# PIC32CM6408PL10032 register map
Vendor: Microchip Technology; Series: PIC32CMPL10; File version: 0
CPU: CM0+ r0p0, little endian, no MPU, no FPU, VTOR, 2 interrupt priority bits, 15 interrupts
Registers are 32-bit, read-write, reset 0x0 unless marked. A register's access mark holds for its fields unless they carry their own. Offsets are from the block's base; [hi:lo] are bit positions; {n}, {i} and the like mark numbered series; 'fields as' and 'values as' point back to an identical list.

## TCC0 — Timer/Counter for Control Applications
Base 0x42001800; register names take the prefix TCC_
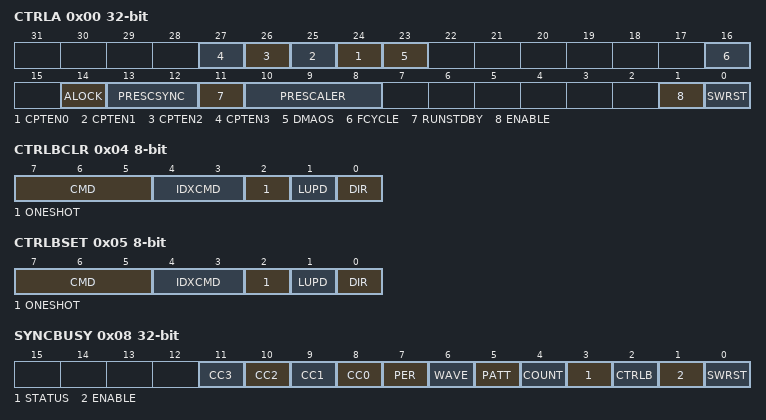
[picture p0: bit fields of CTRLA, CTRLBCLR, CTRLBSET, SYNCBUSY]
0x00 CTRLA — Control A
  [n+24] CPTEN{n} (n=0..3) — Capture Channel {n} Enable
  [23] DMAOS — DMA One-Shot Trigger Mode
  [16] FCYCLE — Full Cycle Enable
  [14] ALOCK — Auto Lock
  [13:12] PRESCSYNC — Prescaler and Counter Synchronization
    0=GCLK (Reload or reset Counter on the next GCLK); 1=PRESC (Reload or reset Counter on the next prescaler clock); 2=RESYNC (Reload or reset Counter on the next GCLK and reset prescaler counter)
  [11] RUNSTDBY — Run in Standby
  [10:8] PRESCALER
    0=DIV1 (Prescaler: GCLK_TCC); 1=DIV2 (Prescaler: GCLK_TCC/2); 2=DIV4 (Prescaler: GCLK_TCC/4); 3=DIV8 (Prescaler: GCLK_TCC/8); 4=DIV16 (Prescaler: GCLK_TCC/16); 5=DIV64 (Prescaler: GCLK_TCC/64); 6=DIV256 (Prescaler: GCLK_TCC/256); 7=DIV1024 (Prescaler: GCLK_TCC/1024)
  [1] ENABLE
  [0] SWRST — Software Reset
0x04 CTRLBCLR 8-bit write-1-clears — Control B Clear
  [7:5] CMD — TCC Command
  [4:3] IDXCMD — Ramp Index Command
  [2] ONESHOT
  [1] LUPD — Lock Update
  [0] DIR — Counter Direction
0x05 CTRLBSET 8-bit write-1-sets — Control B Set
  [7:5] CMD — TCC Command
    0=NONE (No action); 1=RETRIGGER (Force start, restart or retrigger); 2=STOP (Force stop); 3=UPDATE (Force update of double buffered registers); 4=READSYNC (Force a read synchronization of COUNT); 5=DMAOS (One-shot DMA trigger)
  [4:3] IDXCMD — Ramp Index Command
    0=DISABLE (Command disabled: IDX toggles between cycles A and B); 1=SET (Set IDX: Cycle B will be forced in the next cycle); 2=CLEAR (Clear IDX: Cycle A will be forced in next cycle); 3=HOLD (Hold IDX: The next cycle will be the same as the current cycle)
  [2] ONESHOT
  [1] LUPD — Lock Update
  [0] DIR — Counter Direction
0x08 SYNCBUSY ro — Synchronization Busy
  [n+8] CC{n} (n=0..3) — Compare/Capture Channel {n} Synchronization Busy
  [7] PER — PER Synchronization Busy
  [6] WAVE — WAVE Synchronization Busy
  [5] PATT — PATT Synchronization Busy
  [4] COUNT — COUNT Synchronization Busy
  [3] STATUS — STATUS Synchronization Busy
  [2] CTRLB — CTRLB Synchronization Busy
  [1] ENABLE — ENABLE Synchronization Busy
  [0] SWRST — SWRST Synchronization Busy
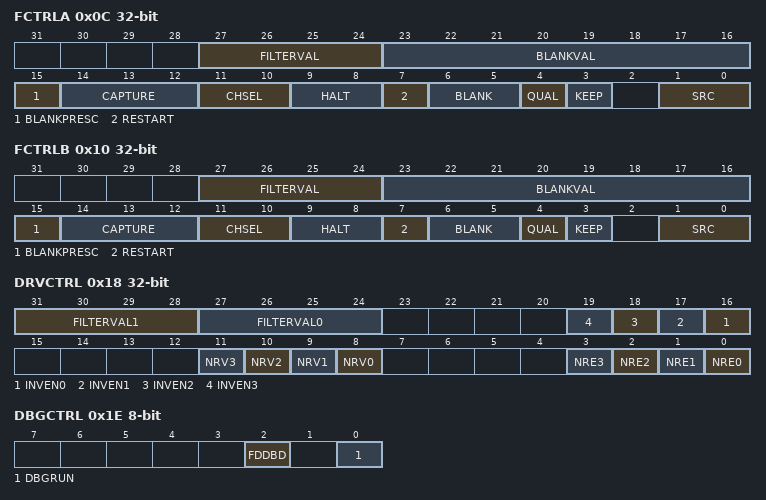
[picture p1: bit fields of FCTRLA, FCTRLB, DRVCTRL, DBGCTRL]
0x0C FCTRLA — Recoverable Fault Control #
  [27:24] FILTERVAL — Recoverable Fault Filter Value
  [23:16] BLANKVAL — Recoverable Fault Blanking Value
  [15] BLANKPRESC — Recoverable Fault Blanking Value Prescaler
  [14:12] CAPTURE — Recoverable Fault Capture Action
    0=DISABLE (Capture on valid recoverable Fault is disabled); 1=CAPT (On the rising edge of a valid recoverable fault, the counter value is captured on the channel selected by CHSEL[1:0]The INTFLAG.FAULTn flag is set on each new captured value.); 2=CAPTMIN (On the rising edge of a valid recoverable fault, the counter value is captured on the channel selected by CHSEL[1:0] if the COUNT value is lower than the last stored capture value (CC).The INTFLAG.FAULTn flag is set on each local minimum detection.); 3=CAPTMAX (On the rising edge of a valid recoverable fault, the counter value is captured on the channel selected by CHSEL[1:0] if the COUNT value is higher than the last stored capture value (CC).The INTFLAG.FAULTn flag is set on each local maximun detection.); 4=LOCMIN (On the rising edge of a valid recoverable fault, the counter value is captured on the channel selected by CHSEL[1:0].The INTFLAG.FAULTn flag is set on each local minimum value detection.); 5=LOCMAX (On the rising edge of a valid recoverable fault, the counter value is captured on the channel selected by CHSEL[1:0].The INTFLAG.FAULTn flag is set on each local maximun detection.); 6=DERIV0 (On the rising edge of a valid recoverable fault, the counter value is captured on the channel selected by CHSEL[1:0].The INTFLAG.FAULTn flag is set on each local maximun or minimum detection.); 7=CAPTMARK (Capture with the ramp index as the MSB value)
  [11:10] CHSEL — Recoverable Fault Capture Channel
    {v}=CC{v} (The captured value stored in CC{v}) (v=0..3)
  [9:8] HALT — Recoverable Fault Halt Operation
    0=DISABLE (Halt action disabled); 1=HW (Hardware halt action); 2=SW (Software halt action); 3=NR (Non-recoverable fault)
  [7] RESTART — Recoverable Fault Restart
  [6:5] BLANK — Recoverable Fault Blanking Operation
    0=START (Blanking is applied from the start of the ramp period); 1=RISE (Blanking is applied from the rising edge of the waveform output); 2=FALL (Blanking is applied from the falling edge of the waveform output); 3=BOTH (Blanking is applied from each toggle of the waveform output)
  [4] QUAL — Recoverable Fault Qualification
  [3] KEEP — Recoverable Fault Keep
  [1:0] SRC — Recoverable Fault Source
    0=DISABLE (Fault input disabled); 1=ENABLE (MCEn (n = 0,1) event input); 2=INVERT (Inverted MCEn (n = 0,1) event input); 3=ALTFAULT (Alternate fault (A or B) state at the end of the previous period.)
0x10 FCTRLB — Recoverable Fault Control #
  fields as FCTRLA
0x14 WEXCTRL — Waveform Extension Control
  [1:0] OTMX — Output Matrix
0x18 DRVCTRL — Driver Control
  [31:28] FILTERVAL1 — Non-Recoverable Fault Input 1 Filter Value
  [27:24] FILTERVAL0 — Non-Recoverable Fault Input 0 Filter Value
  [n+16] INVEN{n} (n=0..3) — Waveform Output {n} Inversion
  [n+8] NRV{n} (n=0..3) — Non-Recoverable State {n} Output Value
  [n] NRE{n} (n=0..3) — Non-Recoverable State {n} Output Enable
0x1E DBGCTRL 8-bit — Debug control
  [2] FDDBD — Fault Detection on Debug Break Detection
  [0] DBGRUN — Debug Running State
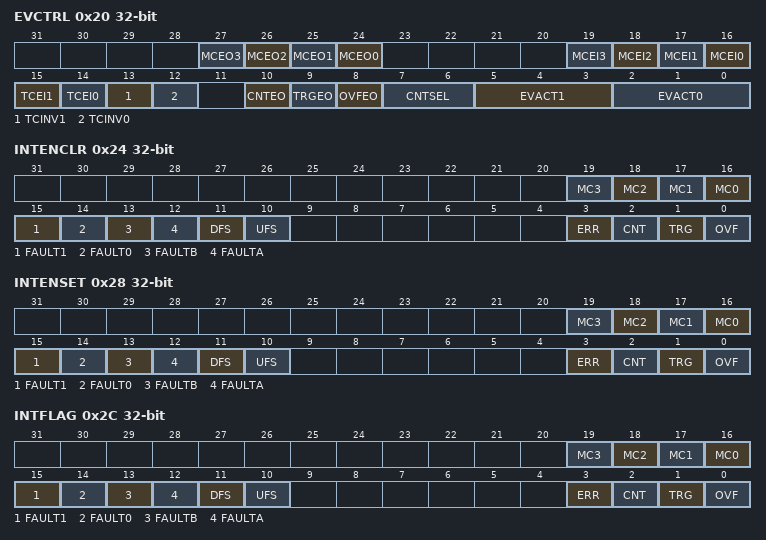
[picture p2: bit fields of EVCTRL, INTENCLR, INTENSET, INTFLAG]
0x20 EVCTRL — Event Control
  [n+24] MCEO{n} (n=0..3) — Match or Capture Channel {n} Event Output Enable
  [n+16] MCEI{n} (n=0..3) — Match or Capture Channel {n} Event Input Enable
  [15] TCEI1 — Timer/Counter Event Input 1 Enable
  [14] TCEI0 — Timer/Counter Event Input 0 Enable
  [13] TCINV1 — Timer/Counter Event 1 Invert Enable
  [12] TCINV0 — Timer/Counter Event 0 Invert Enable
  [10] CNTEO — Timer/Counter Event Output Enable
  [9] TRGEO — Retrigger Event Output Enable
  [8] OVFEO — Overflow/Underflow Event Output Enable
  [7:6] CNTSEL — Timer/Counter Interrupt and Event Output Selection
    0=START (An interrupt/event is generated at the beginning of each counter cycle); 1=END (An interrupt/event is generated at the end of each counter cycle); 3=BOUNDARY (An interrupt/event is generated at the beginning of the first counter cycle, and at the end of last counter cycle)
  [5:3] EVACT1 — Timer/Counter Event Input 1 Action
    0=OFF (Event action disabled); 1=RETRIGGER (Restart or retrigger TCC on event); 2=DIR (Direction control); 3=STOP (Stop TCC on event); 4=DEC (Decrement TCC on event); 6=PWP (Period captured into CC1 Pulse Width on CC0); 7=FAULT (Non-recoverable fault)
  [2:0] EVACT0 — Timer/Counter Event Input 0 Action
    0=OFF (Event action disabled); 1=RETRIGGER (Restart or retrigger TCC on event); 2=COUNTEV (Count on event); 3=START (Start TCC on event); 4=INC (Increment TCC on event); 5=COUNT (Count on the active state of an asynchronous event); 6=STAMP (Capture Time-stamp (overflow)); 7=FAULT (Non-recoverable fault)
0x24 INTENCLR write-1-clears — Interrupt Enable Clear
  [n+16] MC{n} (n=0..3) — Match or Capture Channel {n} Interrupt Enable
  [15] FAULT1 — Non-Recoverable Fault 1 Interrupt Enable
  [14] FAULT0 — Non-Recoverable Fault 0 Interrupt Enable
  [13] FAULTB — Recoverable Fault B Interrupt Enable
  [12] FAULTA — Recoverable Fault A Interrupt Enable
  [11] DFS — Non-Recoverable Debug Fault Interrupt Enable
  [10] UFS — Non-Recoverable Update Fault Interrupt Enable
  [3] ERR — Error Interrupt Enable
  [2] CNT — Counter Interrupt Enable
  [1] TRG — Retrigger Interrupt Enable
  [0] OVF — Overflow Interrupt Enable
0x28 INTENSET write-1-sets — Interrupt Enable Set
  fields as INTENCLR
0x2C INTFLAG write-1-clears — Interrupt Flag Status and Clear
  [n+16] MC{n} (n=0..3) — Match or Capture Channel {n} Interrupt Flag
  [15] FAULT1 — Non-Recoverable Fault 1 Interrupt Flag
  [14] FAULT0 — Non-Recoverable Fault 0 Interrupt Flag
  [13] FAULTB — Recoverable Fault B Interrupt Flag
  [12] FAULTA — Recoverable Fault A Interrupt Flag
  [11] DFS — Non-Recoverable Debug Fault State Interrupt Flag
  [10] UFS — Non-Recoverable Update Fault
  [3] ERR — Error Interrupt Flag
  [2] CNT — Counter Interrupt Flag
  [1] TRG — Retrigger Interrupt Flag
  [0] OVF — Overflow Interrupt Flag
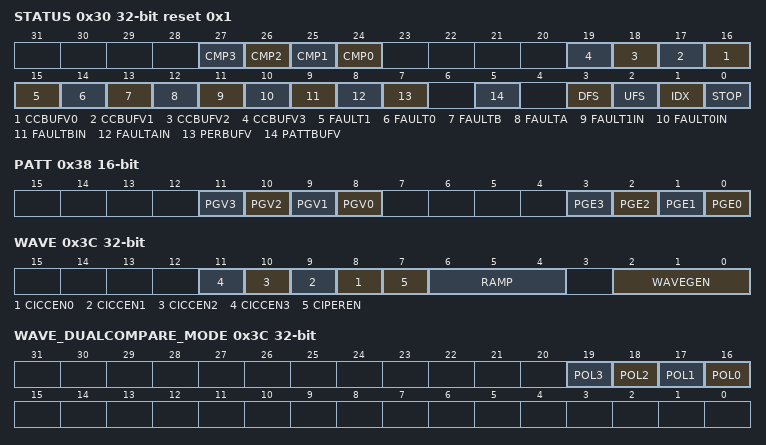
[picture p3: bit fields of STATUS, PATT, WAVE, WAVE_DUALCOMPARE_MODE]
0x30 STATUS reset 0x1
  [n+24] CMP{n} (n=0..3) — Compare Channel {n} Value
  [n+16] CCBUFV{n} (n=0..3) — Compare/Capture Channel {n} Buffer Valid
  [15] FAULT1 — Non-recoverable Fault 1 State
  [14] FAULT0 — Non-recoverable Fault 0 State
  [13] FAULTB — Recoverable Fault B State
  [12] FAULTA — Recoverable Fault A State
  [11] FAULT1IN — Non-Recoverable Fault 1 Input
  [10] FAULT0IN — Non-Recoverable Fault 0 Input
  [9] FAULTBIN — Recoverable Fault B Input
  [8] FAULTAIN — Recoverable Fault A Input
  [7] PERBUFV — Period Buffer Valid
  [5] PATTBUFV — Pattern Generator Value Buffer Valid
  [3] DFS — Debug Fault State
  [2] UFS — Non-recoverable Update Fault State
  [1] IDX — Ramp Index
  [0] STOP
0x34 COUNT — Counter
  [15:0] COUNT — Counter Value
0x38 PATT 16-bit — Pattern
  [n+8] PGV{n} (n=0..3) — Pattern Generation Output {n} Value
  [n] PGE{n} (n=0..3) — Pattern Generation Output {n} Enable
0x3C WAVE — Waveform
  [n+8] CICCEN{n} (n=0..3) — Circular Compare/Capture Channel {n} Enable
  [7] CIPEREN — Circular Period Enable
  [6:4] RAMP — Ramp Operation
    0=RAMP1 operation; 1=RAMP2A (Alternative RAMP2 operation); 2=RAMP2 operation; 3=RAMP2C (Critical RAMP2 operation)
  [2:0] WAVEGEN — Waveform Generation Operation
    0=NFRQ (Normal Frequency); 1=MFRQ (Match Frequency); 2=NPWM (Normal PWM); 3=DPWM (Dual Compare PWM); 4=DSCRITICAL (Dual-slope PWM); 5=DSBOTTOM (Dual-slope PWM); 6=DSBOTH (Dual-slope PWM); 7=DSTOP (Dual-slope PWM)
0x3C WAVE_DUALCOMPARE_MODE (alternate view of WAVE) — Waveform
  [all] fields
    0=NORMAL (Compare output is initialized to ~DIR, set to DIR when TCC counter matches CCn value and set to ~DIR when TCC counter matches CC[n+WO_NUM/2] value.); 1=INVERTED (Compare output is initialized to DIR, set to ~DIR when TCC counter matches CCn value and set to DIR when TCC counter matches CC[n+WO_NUM/2] value.)
  [n+16] POL{n} (n=0..3) — Channel {n} Polarity
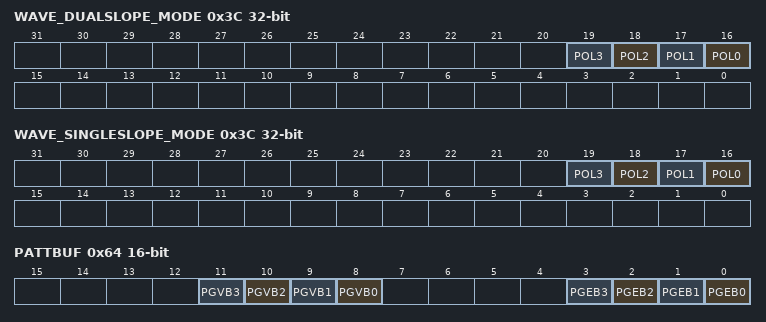
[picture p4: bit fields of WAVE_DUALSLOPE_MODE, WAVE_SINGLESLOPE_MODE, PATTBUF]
0x3C WAVE_DUALSLOPE_MODE (alternate view of WAVE) — Waveform
  [all] fields
    0=NORMAL (Compare output is set to ~DIR when TCC counter matches CCn value); 1=INVERTED (Compare output is set to DIR when TCC counter matches CCn value.)
  [n+16] POL{n} (n=0..3) — Channel {n} Polarity
0x3C WAVE_SINGLESLOPE_MODE (alternate view of WAVE) — Waveform
  [all] fields
    0=NORMAL (Compare output is initialized to ~DIR and set to DIR when TCC counter matches CCn value.); 1=INVERTED (Compare output is initialized to DIR and set to ~DIR when TCC counter matches CCn value.)
  [n+16] POL{n} (n=0..3) — Channel {n} Polarity
0x40 PER reset 0xFFFFFFFF — Period
  [15:0] PER — Period Value
{0x44+4i} CC[{i}] (i=0..3) — Compare/Capture Channel #
  [15:0] CC — Compare/Capture Channel Value
0x64 PATTBUF 16-bit — Pattern Buffer
  [n+8] PGVB{n} (n=0..3) — Pattern Generation Output Value Buffer {n}
  [n] PGEB{n} (n=0..3) — Pattern Generation Output Enable Buffer {n}
0x6C PERBUF reset 0xFFFFFFFF — Period Buffer
  [15:0] PERBUF — Period Buffer Value
{0x70+4i} CCBUF[{i}] (i=0..3) — Compare/Capture Channel # Buffer
  [15:0] CCBUF — Compare/Capture Channel Buffer Value
